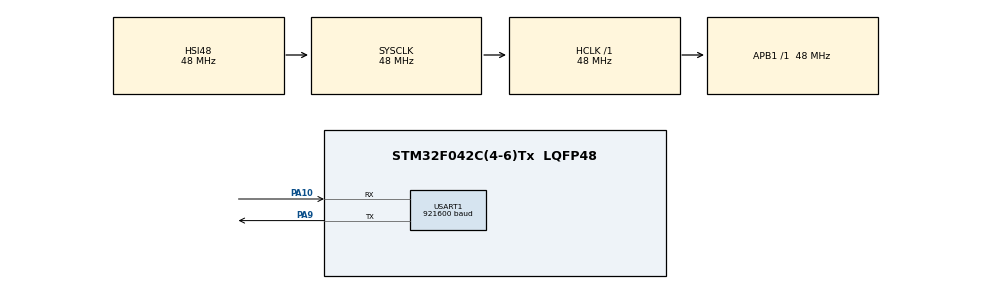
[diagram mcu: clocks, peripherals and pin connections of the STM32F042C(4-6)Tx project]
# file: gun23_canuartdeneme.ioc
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Mcu.Family=STM32F0
Mcu.Name=STM32F042C(4-6)Tx
Mcu.Package=LQFP48
NVIC.USART1_IRQn=true\:0\:0\:false\:false\:true\:true\:true\:true
PA10.Mode=Asynchronous
PA10.Signal=USART1_RX
PA13.Mode=Serial_Wire
PA13.Signal=SYS_SWDIO
PA14.Mode=Serial_Wire
PA14.Signal=SYS_SWCLK
PA9.Mode=Asynchronous
PA9.Signal=USART1_TX
ProjectManager.HeapSize=0x200
ProjectManager.StackSize=0x400
ProjectManager.TargetToolchain=STM32CubeIDE
RCC.AHBFreq_Value=48000000
RCC.APB1Freq_Value=48000000
RCC.APB1TimFreq_Value=48000000
RCC.HCLKFreq_Value=48000000
RCC.SYSCLKFreq_VALUE=48000000
RCC.SYSCLKSource=RCC_SYSCLKSOURCE_HSI48
TIM14.Period=999
TIM14.Prescaler=4
USART1.BaudRate=921600
USART1.VirtualMode-Asynchronous=VM_ASYNC
VP_TIM14_VS_ClockSourceINT.Mode=Enable_Timer
board=custom

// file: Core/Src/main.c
/* USER CODE BEGIN Header */
/**
  ******************************************************************************
  * @file           : main.c
  * @brief          : Main program body
  ******************************************************************************
  * @attention
  *
  * Copyright (c) 2022 STMicroelectronics.
  * All rights reserved.
  *
  * This software is licensed under terms that can be found in the LICENSE file
  * in the root directory of this software component.
  * If no LICENSE file comes with this software, it is provided AS-IS.
  *
  ******************************************************************************
  */
/* USER CODE END Header */
#include "main.h"

/* USER CODE BEGIN Includes */
#include "string.h"
/* USER CODE END Includes */

 TIM_HandleTypeDef htim14;

UART_HandleTypeDef huart1;

/* USER CODE BEGIN PV */
uint8_t rxData[25];

/* USER CODE END PV */

void SystemClock_Config(void);
static void MX_GPIO_Init(void);
static void MX_TIM14_Init(void);
static void MX_USART1_UART_Init(void);
/* USER CODE BEGIN PFP */
void HAL_UART_RxCpltCallback(UART_HandleTypeDef *huart)
{

	HAL_UART_Receive_IT(huart, rxData, 25);

    memset(rxData,0,25);
}

/* USER CODE END PFP */

int main(void)
{

  /* MCU Configuration--------------------------------------------------------*/

  /* Reset of all peripherals, Initializes the Flash interface and the Systick. */
  HAL_Init();

  /* Configure the system clock */
  SystemClock_Config();

  /* Initialize all configured peripherals */
  MX_GPIO_Init();
  MX_TIM14_Init();
  MX_USART1_UART_Init();
  /* USER CODE BEGIN 2 */

HAL_UART_Receive_IT(&huart1, rxData, 25);
  /* USER CODE END 2 */

  /* Infinite loop */
  while (1)
  {

  }
}

void SystemClock_Config(void)
{
  RCC_OscInitTypeDef RCC_OscInitStruct = {0};
  RCC_ClkInitTypeDef RCC_ClkInitStruct = {0};
  RCC_PeriphCLKInitTypeDef PeriphClkInit = {0};

  /** Initializes the RCC Oscillators according to the specified parameters
  * in the RCC_OscInitTypeDef structure.
  */
  RCC_OscInitStruct.OscillatorType = RCC_OSCILLATORTYPE_HSI48;
  RCC_OscInitStruct.HSI48State = RCC_HSI48_ON;
  RCC_OscInitStruct.PLL.PLLState = RCC_PLL_NONE;
  if (HAL_RCC_OscConfig(&RCC_OscInitStruct) != HAL_OK)
  {
    Error_Handler();
  }

  /** Initializes the CPU, AHB and APB buses clocks
  */
  RCC_ClkInitStruct.ClockType = RCC_CLOCKTYPE_HCLK|RCC_CLOCKTYPE_SYSCLK
                              |RCC_CLOCKTYPE_PCLK1;
  RCC_ClkInitStruct.SYSCLKSource = RCC_SYSCLKSOURCE_HSI48;
  RCC_ClkInitStruct.AHBCLKDivider = RCC_SYSCLK_DIV1;
  RCC_ClkInitStruct.APB1CLKDivider = RCC_HCLK_DIV1;

  if (HAL_RCC_ClockConfig(&RCC_ClkInitStruct, FLASH_LATENCY_1) != HAL_OK)
  {
    Error_Handler();
  }
  PeriphClkInit.PeriphClockSelection = RCC_PERIPHCLK_USART1;
  PeriphClkInit.Usart1ClockSelection = RCC_USART1CLKSOURCE_PCLK1;
  if (HAL_RCCEx_PeriphCLKConfig(&PeriphClkInit) != HAL_OK)
  {
    Error_Handler();
  }
}

static void MX_TIM14_Init(void)
{

  htim14.Instance = TIM14;
  htim14.Init.Prescaler = 4;
  htim14.Init.CounterMode = TIM_COUNTERMODE_UP;
  htim14.Init.Period = 999;
  htim14.Init.ClockDivision = TIM_CLOCKDIVISION_DIV1;
  htim14.Init.AutoReloadPreload = TIM_AUTORELOAD_PRELOAD_DISABLE;
  if (HAL_TIM_Base_Init(&htim14) != HAL_OK)
  {
    Error_Handler();
  }

}

static void MX_USART1_UART_Init(void)
{

  huart1.Instance = USART1;
  huart1.Init.BaudRate = 921600;
  huart1.Init.WordLength = UART_WORDLENGTH_8B;
  huart1.Init.StopBits = UART_STOPBITS_1;
  huart1.Init.Parity = UART_PARITY_NONE;
  huart1.Init.Mode = UART_MODE_TX_RX;
  huart1.Init.HwFlowCtl = UART_HWCONTROL_NONE;
  huart1.Init.OverSampling = UART_OVERSAMPLING_16;
  huart1.Init.OneBitSampling = UART_ONE_BIT_SAMPLE_DISABLE;
  huart1.AdvancedInit.AdvFeatureInit = UART_ADVFEATURE_NO_INIT;
  if (HAL_UART_Init(&huart1) != HAL_OK)
  {
    Error_Handler();
  }

}

static void MX_GPIO_Init(void)
{

  /* GPIO Ports Clock Enable */
  __HAL_RCC_GPIOA_CLK_ENABLE();

}

void Error_Handler(void)
{
  __disable_irq();
  while (1)
  {
  }
}
